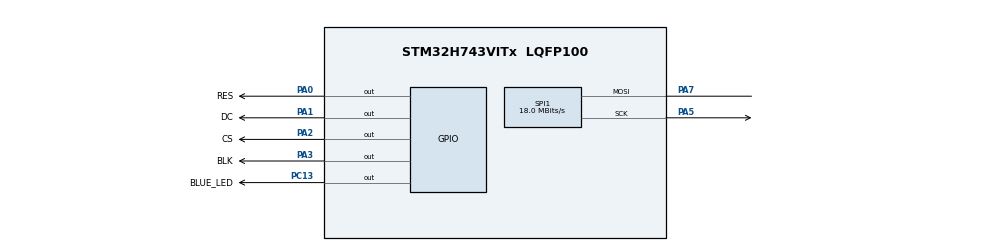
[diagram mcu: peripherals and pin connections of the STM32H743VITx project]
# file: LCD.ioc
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FREERTOS.Tasks01=defaultTask,24,128,StartDefaultTask,Default,NULL,Dynamic,NULL,NULL;LEDTask,24,128,StartLEDTask,Default,NULL,Dynamic,NULL,NULL;LvglTimer_Task,24,512,StartLvglTimerTask,Default,NULL,Dynamic,NULL,NULL;LVGLTask,24,512,StartLVGLTask,Default,NULL,Dynamic,NULL,NULL
Mcu.Family=STM32H7
Mcu.Name=STM32H743VITx
Mcu.Package=LQFP100
NVIC.PriorityGroup=NVIC_PRIORITYGROUP_4
NVIC.TIM1_UP_IRQn=true\:15\:0\:false\:false\:true\:false\:false\:true\:true
NVIC.TimeBase=TIM1_UP_IRQn
NVIC.TimeBaseIP=TIM1
PA0.GPIO_Label=RES
PA0.GPIO_PuPd=GPIO_NOPULL
PA0.GPIO_Speed=GPIO_SPEED_FREQ_HIGH
PA0.PinState=GPIO_PIN_SET
PA0.Signal=GPIO_Output
PA1.GPIO_Label=DC
PA1.GPIO_PuPd=GPIO_NOPULL
PA1.GPIO_Speed=GPIO_SPEED_FREQ_HIGH
PA1.PinState=GPIO_PIN_SET
PA1.Signal=GPIO_Output
PA2.GPIO_Label=CS
PA2.GPIO_PuPd=GPIO_NOPULL
PA2.GPIO_Speed=GPIO_SPEED_FREQ_HIGH
PA2.PinState=GPIO_PIN_SET
PA2.Signal=GPIO_Output
PA3.GPIO_Label=BLK
PA3.GPIO_PuPd=GPIO_NOPULL
PA3.GPIO_Speed=GPIO_SPEED_FREQ_HIGH
PA3.PinState=GPIO_PIN_SET
PA3.Signal=GPIO_Output
PA5.Mode=Simplex_Bidirectional_Master
PA5.Signal=SPI1_SCK
PA7.Mode=Simplex_Bidirectional_Master
PA7.Signal=SPI1_MOSI
PC13.GPIO_Label=BLUE_LED
PC13.Signal=GPIO_Output
PH0-OSC_IN\ (PH0).Mode=HSE-External-Oscillator
PH0-OSC_IN\ (PH0).Signal=RCC_OSC_IN
PH1-OSC_OUT\ (PH1).Mode=HSE-External-Oscillator
PH1-OSC_OUT\ (PH1).Signal=RCC_OSC_OUT
ProjectManager.HeapSize=0x200
ProjectManager.StackSize=0x400
ProjectManager.TargetToolchain=Makefile
RCC.ADCFreq_Value=480000000
RCC.APB1Freq_Value=36000000
RCC.APB2Freq_Value=36000000
RCC.APB3Freq_Value=36000000
RCC.APB4Freq_Value=36000000
RCC.CKPERSourceSelection=RCC_CLKPSOURCE_HSE
RCC.CortexFreq_Value=72000000
RCC.D1CPRE=RCC_SYSCLK_DIV2
RCC.DIVM1=1
RCC.DIVM2=1
RCC.DIVM3=1
RCC.DIVN1=36
RCC.DIVN2=120
RCC.DIVN3=27
RCC.DIVP3=3
RCC.HCLKFreq_Value=36000000
RCC.HPRE=RCC_HCLK_DIV2
RCC.HSE_VALUE=8000000
RCC.PLL3FRACN=0
RCC.PLLFRACN=0
RCC.PLLSourceVirtual=RCC_PLLSOURCE_HSE
RCC.SPI123CLockSelection=RCC_SPI123CLKSOURCE_PLL3
RCC.SYSCLKFreq_VALUE=144000000
RCC.SYSCLKSource=RCC_SYSCLKSOURCE_PLLCLK
RCC.USBFreq_Value=144000000
SPI1.BaudRatePrescaler=SPI_BAUDRATEPRESCALER_4
SPI1.CLKPhase=SPI_PHASE_1EDGE
SPI1.CLKPolarity=SPI_POLARITY_HIGH
SPI1.CalculateBaudRate=18.0 MBits/s
SPI1.DataSize=SPI_DATASIZE_8BIT
SPI1.Direction=SPI_DIRECTION_1LINE
SPI1.Mode=SPI_MODE_MASTER
SPI1.NSSPMode=SPI_NSS_PULSE_DISABLE
SPI1.VirtualType=VM_MASTER
VP_FREERTOS_VS_CMSIS_V2.Mode=CMSIS_V2
VP_SYS_VS_tim1.Mode=TIM1
board=custom

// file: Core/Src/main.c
/* USER CODE BEGIN Header */
/**
  ******************************************************************************
  * @file           : main.c
  * @brief          : Main program body
  ******************************************************************************
  * @attention
  *
  * Copyright (c) 2023 STMicroelectronics.
  * All rights reserved.
  *
  * This software is licensed under terms that can be found in the LICENSE file
  * in the root directory of this software component.
  * If no LICENSE file comes with this software, it is provided AS-IS.
  *
  ******************************************************************************
  */
/* USER CODE END Header */
#include "main.h"
#include "cmsis_os.h"
#include "spi.h"
#include "gpio.h"

/* USER CODE BEGIN Includes */

#include "lv_demo_stress.h"

/* USER CODE END Includes */

void SystemClock_Config(void);
void MX_FREERTOS_Init(void);

int main(void)
{

  /* MCU Configuration--------------------------------------------------------*/

  /* Reset of all peripherals, Initializes the Flash interface and the Systick. */
  HAL_Init();

  /* Configure the system clock */
  SystemClock_Config();

  /* Initialize all configured peripherals */
  MX_GPIO_Init();
  MX_SPI1_Init();

  /* Init scheduler */
  osKernelInitialize();  /* Call init function for freertos objects (in freertos.c) */
  MX_FREERTOS_Init();

  /* Start scheduler */
  osKernelStart();
  /* We should never get here as control is now taken by the scheduler */
  /* Infinite loop */
  while (1)
  {

  }
}

void SystemClock_Config(void)
{
  RCC_OscInitTypeDef RCC_OscInitStruct = {0};
  RCC_ClkInitTypeDef RCC_ClkInitStruct = {0};

  /** Supply configuration update enable
  */
  HAL_PWREx_ConfigSupply(PWR_LDO_SUPPLY);

  /** Configure the main internal regulator output voltage
  */
  __HAL_PWR_VOLTAGESCALING_CONFIG(PWR_REGULATOR_VOLTAGE_SCALE3);

  while(!__HAL_PWR_GET_FLAG(PWR_FLAG_VOSRDY)) {}

  /** Initializes the RCC Oscillators according to the specified parameters
  * in the RCC_OscInitTypeDef structure.
  */
  RCC_OscInitStruct.OscillatorType = RCC_OSCILLATORTYPE_HSE;
  RCC_OscInitStruct.HSEState = RCC_HSE_ON;
  RCC_OscInitStruct.PLL.PLLState = RCC_PLL_ON;
  RCC_OscInitStruct.PLL.PLLSource = RCC_PLLSOURCE_HSE;
  RCC_OscInitStruct.PLL.PLLM = 1;
  RCC_OscInitStruct.PLL.PLLN = 36;
  RCC_OscInitStruct.PLL.PLLP = 2;
  RCC_OscInitStruct.PLL.PLLQ = 2;
  RCC_OscInitStruct.PLL.PLLR = 2;
  RCC_OscInitStruct.PLL.PLLRGE = RCC_PLL1VCIRANGE_3;
  RCC_OscInitStruct.PLL.PLLVCOSEL = RCC_PLL1VCOWIDE;
  RCC_OscInitStruct.PLL.PLLFRACN = 0;
  if (HAL_RCC_OscConfig(&RCC_OscInitStruct) != HAL_OK)
  {
    Error_Handler();
  }

  /** Initializes the CPU, AHB and APB buses clocks
  */
  RCC_ClkInitStruct.ClockType = RCC_CLOCKTYPE_HCLK|RCC_CLOCKTYPE_SYSCLK
                              |RCC_CLOCKTYPE_PCLK1|RCC_CLOCKTYPE_PCLK2
                              |RCC_CLOCKTYPE_D3PCLK1|RCC_CLOCKTYPE_D1PCLK1;
  RCC_ClkInitStruct.SYSCLKSource = RCC_SYSCLKSOURCE_PLLCLK;
  RCC_ClkInitStruct.SYSCLKDivider = RCC_SYSCLK_DIV2;
  RCC_ClkInitStruct.AHBCLKDivider = RCC_HCLK_DIV2;
  RCC_ClkInitStruct.APB3CLKDivider = RCC_APB3_DIV1;
  RCC_ClkInitStruct.APB1CLKDivider = RCC_APB1_DIV1;
  RCC_ClkInitStruct.APB2CLKDivider = RCC_APB2_DIV1;
  RCC_ClkInitStruct.APB4CLKDivider = RCC_APB4_DIV1;

  if (HAL_RCC_ClockConfig(&RCC_ClkInitStruct, FLASH_LATENCY_0) != HAL_OK)
  {
    Error_Handler();
  }
}

void HAL_TIM_PeriodElapsedCallback(TIM_HandleTypeDef *htim)
{
  if (htim->Instance == TIM1) {
    HAL_IncTick();
  }
}

void Error_Handler(void)
{
  __disable_irq();
  while (1)
  {
  }
}

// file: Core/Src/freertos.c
/* USER CODE BEGIN Header */
/**
  ******************************************************************************
  * File Name          : freertos.c
  * Description        : Code for freertos applications
  ******************************************************************************
  * @attention
  *
  * Copyright (c) 2023 STMicroelectronics.
  * All rights reserved.
  *
  * This software is licensed under terms that can be found in the LICENSE file
  * in the root directory of this software component.
  * If no LICENSE file comes with this software, it is provided AS-IS.
  *
  ******************************************************************************
  */
/* USER CODE END Header */

#include "FreeRTOS.h"
#include "task.h"
#include "main.h"
#include "cmsis_os.h"

/* USER CODE BEGIN Includes */
#include "lvgl.h"
#include "lv_demos.h"
#include "st7789.h"
/* USER CODE END Includes */

/* Definitions for defaultTask */
osThreadId_t defaultTaskHandle;
const osThreadAttr_t defaultTask_attributes = {
  .name = "defaultTask",
  .stack_size = 128 * 4,
  .priority = (osPriority_t) osPriorityNormal,
};
/* Definitions for LEDTask */
osThreadId_t LEDTaskHandle;
const osThreadAttr_t LEDTask_attributes = {
  .name = "LEDTask",
  .stack_size = 128 * 4,
  .priority = (osPriority_t) osPriorityNormal,
};
/* Definitions for LvglTimer_Task */
osThreadId_t LvglTimer_TaskHandle;
const osThreadAttr_t LvglTimer_Task_attributes = {
  .name = "LvglTimer_Task",
  .stack_size = 512 * 4,
  .priority = (osPriority_t) osPriorityNormal,
};
/* Definitions for LVGLTask */
osThreadId_t LVGLTaskHandle;
const osThreadAttr_t LVGLTask_attributes = {
  .name = "LVGLTask",
  .stack_size = 512 * 4,
  .priority = (osPriority_t) osPriorityNormal,
};

void StartDefaultTask(void *argument);
void StartLEDTask(void *argument);
void StartLvglTimerTask(void *argument);
void StartLVGLTask(void *argument);

void MX_FREERTOS_Init(void); /* (MISRA C 2004 rule 8.1) */

void MX_FREERTOS_Init(void) {

  /* Create the thread(s) */
  /* creation of defaultTask */
  defaultTaskHandle = osThreadNew(StartDefaultTask, NULL, &defaultTask_attributes);

  /* creation of LEDTask */
  LEDTaskHandle = osThreadNew(StartLEDTask, NULL, &LEDTask_attributes);

  /* creation of LvglTimer_Task */
  LvglTimer_TaskHandle = osThreadNew(StartLvglTimerTask, NULL, &LvglTimer_Task_attributes);

  /* creation of LVGLTask */
  LVGLTaskHandle = osThreadNew(StartLVGLTask, NULL, &LVGLTask_attributes);

}

void StartDefaultTask(void *argument)
{
  for(;;)
  {
    osDelay(1);
  }
}

void StartLEDTask(void *argument)
{
  /* USER CODE BEGIN StartLEDTask */
  /* Infinite loop */
  for(;;)
  {
    osDelay(50);
    // LL_GPIO_TogglePin(BLUE_LED_GPIO_Port,BLUE_LED_Pin);
    HAL_GPIO_TogglePin(BLUE_LED_GPIO_Port,BLUE_LED_Pin);
    osDelay(50);
  }
  /* USER CODE END StartLEDTask */
}

void StartLvglTimerTask(void *argument)
{
  /* USER CODE BEGIN StartLvglTimerTask */
  /* Infinite loop */
  for(;;)
  {
    lv_timer_handler();
    osDelay(5);
  }
  /* USER CODE END StartLvglTimerTask */
}

void StartLVGLTask(void *argument)
{
  /* USER CODE BEGIN StartLVGLTask */
  lv_init();					//LVGL初始化
	// lv_port_disp_init();
// lv_port_indev_init();
  // ST7789_Init();
  Display_init(0);
  // osDelay(50);
  //  ST7789_Test();
  lv_demo_stress();
  /* Infinite loop */
  for(;;)
  {
    // osDelay(500);
    osDelay(1);
  }
  /* USER CODE END StartLVGLTask */
}

/* USER CODE BEGIN Application */
void vApplicationTickHook(void)
{
  lv_tick_inc(1);
}
/* USER CODE END Application */
